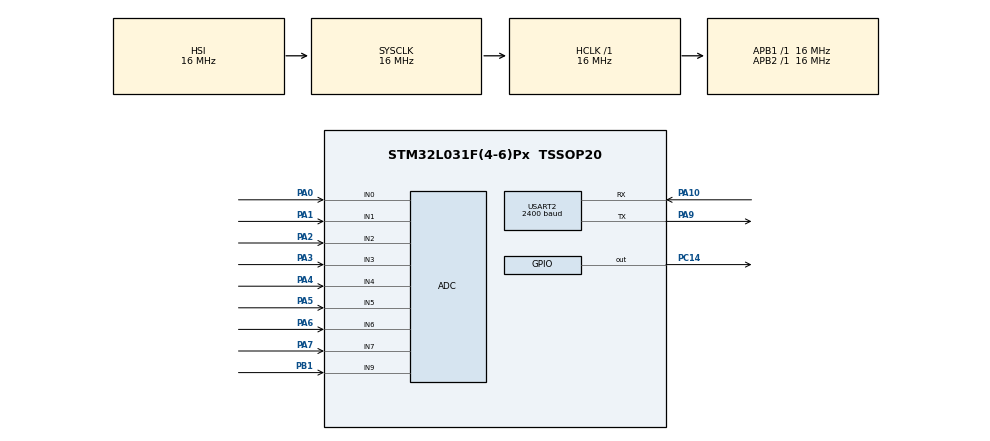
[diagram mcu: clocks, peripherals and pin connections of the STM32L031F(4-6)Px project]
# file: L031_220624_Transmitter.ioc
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Mcu.Family=STM32L0
RCC.MSI_VALUE=2097000
PA6.Mode=IN6
PA7.Mode=IN7
USART2.DMADisableonRxErrorParam=ADVFEATURE_DMA_DISABLEONRXERROR
PA10.Mode=Asynchronous
Dma.ADC.0.Mode=DMA_CIRCULAR
PA0-CK_IN.Mode=IN0
USART2.Parity=PARITY_EVEN
Dma.ADC.0.Priority=DMA_PRIORITY_VERY_HIGH
PC14-OSC32_IN.Signal=GPIO_Output
ADC.ClockPrescaler=ADC_CLOCK_ASYNC_DIV16
USART2.BaudRate=2400
RCC.SYSCLKSource=RCC_SYSCLKSOURCE_HSI
ProjectManager.StackSize=0x400
Dma.ADC.0.PeriphDataAlignment=DMA_PDATAALIGN_HALFWORD
PA3.Mode=IN3
PA13.Signal=SYS_SWDIO
ADC.DiscontinuousConvMode=DISABLE
RCC.HSI16_VALUE=16000000
PA9.Mode=Asynchronous
RCC.PLLDIV=RCC_PLLDIV_4
PA4.Mode=IN4
ProjectManager.TargetToolchain=STM32CubeIDE
Dma.ADC.0.PeriphInc=DMA_PINC_DISABLE
RCC.HCLKFreq_Value=16000000
RCC.APB2TimFreq_Value=16000000
PA9.Signal=USART2_TX
RCC.LSE_VALUE=32768
PA1.Signal=ADC_IN1
RCC.AHBFreq_Value=16000000
Dma.ADC.0.Direction=DMA_PERIPH_TO_MEMORY
ADC.SamplingTime=ADC_SAMPLETIME_160CYCLES_5
PA5.Signal=ADC_IN5
RCC.HSE_VALUE=8000000
ADC.DMAContinuousRequests=ENABLE
board=custom
USART2.VirtualMode-Asynchronous=VM_ASYNC
RCC.VCOOutputFreq_Value=64000000
RCC.PLLMUL=RCC_PLLMUL_4
PA0-CK_IN.Signal=ADC_IN0
RCC.APB2Freq_Value=16000000
PA1.Mode=IN1
ADC.ExternalTrigConvEdge=ADC_EXTERNALTRIGCONVEDGE_NONE
PA14.Mode=Serial_Wire
RCC.ADCFreq_Value=16000000
ADC.EOCSelection=ADC_EOC_SEQ_CONV
PA13.Mode=Serial_Wire
Mcu.Name=STM32L031F(4-6)Px
PA2.Signal=ADC_IN2
ADC.Overrun=ADC_OVR_DATA_OVERWRITTEN
Dma.ADC.0.MemInc=DMA_MINC_ENABLE
PA4.Signal=ADC_IN4
RCC.SYSCLKFreq_VALUE=16000000
Mcu.Package=TSSOP20
PA6.Signal=ADC_IN6
PB1.Signal=ADC_IN9
Dma.ADC.0.Instance=DMA1_Channel1
PA10.Signal=USART2_RX
PA14.Signal=SYS_SWCLK
ProjectManager.HeapSize=0x200
PB1.Mode=IN9
RCC.HSI_VALUE=16000000
Dma.ADC.0.MemDataAlignment=DMA_MDATAALIGN_HALFWORD
RCC.APB1TimFreq_Value=16000000
PA2.Mode=IN2
PC14-OSC32_IN.GPIO_PuPd=GPIO_PULLDOWN
NVIC.DMA1_Channel1_IRQn=true\:0\:0\:false\:false\:true\:false\:true
Dma.Request0=ADC
RCC.APB1Freq_Value=16000000
USART2.Mode=MODE_TX_RX
ADC.ContinuousConvMode=ENABLE
ADC.ExternalTrigConv=ADC_SOFTWARE_START
PA3.Signal=ADC_IN3
PA7.Signal=ADC_IN7
PA5.Mode=IN5
USART2.OverrunDisableParam=ADVFEATURE_OVERRUN_DISABLE

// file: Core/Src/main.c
/* USER CODE BEGIN Header */
/**
  ******************************************************************************
  * @file           : main.c
  * @brief          : Main program body
  ******************************************************************************
  * @attention
  *
  * <h2><center>&copy; Copyright (c) 2022 STMicroelectronics.
  * All rights reserved.</center></h2>
  *
  * This software component is licensed by ST under BSD 3-Clause license,
  * the "License"; You may not use this file except in compliance with the
  * License. You may obtain a copy of the License at:
  *                        opensource.org/licenses/BSD-3-Clause
  *
  ******************************************************************************
  */
/* USER CODE END Header */
#include "main.h"

/* USER CODE BEGIN Includes */
#include "stdio.h"
#include "adc.h"
#include "processing.h"
#include "transmission.h"

/* USER CODE END Includes */

ADC_HandleTypeDef hadc;
DMA_HandleTypeDef hdma_adc;

UART_HandleTypeDef huart2;

void SystemClock_Config(void);
static void MX_GPIO_Init(void);
static void MX_DMA_Init(void);
static void MX_ADC_Init(void);
static void MX_USART2_UART_Init(void);

int main(void)
{

  /* MCU Configuration--------------------------------------------------------*/

  /* Reset of all peripherals, Initializes the Flash interface and the Systick. */
  HAL_Init();

  /* Configure the system clock */
  SystemClock_Config();

  /* Initialize all configured peripherals */
  MX_GPIO_Init();
  MX_DMA_Init();
  MX_ADC_Init();
  MX_USART2_UART_Init();
  /* USER CODE BEGIN 2 */
  HAL_ADC_Start_DMA(&hadc, (uint32_t *)adcBuffer, buffLength);

  /* USER CODE END 2 */

  /* Infinite loop */
  while (1)
  {

  }
}

void SystemClock_Config(void)
{
  RCC_OscInitTypeDef RCC_OscInitStruct = {0};
  RCC_ClkInitTypeDef RCC_ClkInitStruct = {0};
  RCC_PeriphCLKInitTypeDef PeriphClkInit = {0};

  /** Configure the main internal regulator output voltage
  */
  __HAL_PWR_VOLTAGESCALING_CONFIG(PWR_REGULATOR_VOLTAGE_SCALE1);
  /** Initializes the RCC Oscillators according to the specified parameters
  * in the RCC_OscInitTypeDef structure.
  */
  RCC_OscInitStruct.OscillatorType = RCC_OSCILLATORTYPE_HSI;
  RCC_OscInitStruct.HSIState = RCC_HSI_ON;
  RCC_OscInitStruct.HSICalibrationValue = RCC_HSICALIBRATION_DEFAULT;
  RCC_OscInitStruct.PLL.PLLState = RCC_PLL_NONE;
  if (HAL_RCC_OscConfig(&RCC_OscInitStruct) != HAL_OK)
  {
    Error_Handler();
  }
  /** Initializes the CPU, AHB and APB buses clocks
  */
  RCC_ClkInitStruct.ClockType = RCC_CLOCKTYPE_HCLK|RCC_CLOCKTYPE_SYSCLK
                              |RCC_CLOCKTYPE_PCLK1|RCC_CLOCKTYPE_PCLK2;
  RCC_ClkInitStruct.SYSCLKSource = RCC_SYSCLKSOURCE_HSI;
  RCC_ClkInitStruct.AHBCLKDivider = RCC_SYSCLK_DIV1;
  RCC_ClkInitStruct.APB1CLKDivider = RCC_HCLK_DIV1;
  RCC_ClkInitStruct.APB2CLKDivider = RCC_HCLK_DIV1;

  if (HAL_RCC_ClockConfig(&RCC_ClkInitStruct, FLASH_LATENCY_0) != HAL_OK)
  {
    Error_Handler();
  }
  PeriphClkInit.PeriphClockSelection = RCC_PERIPHCLK_USART2;
  PeriphClkInit.Usart2ClockSelection = RCC_USART2CLKSOURCE_PCLK1;
  if (HAL_RCCEx_PeriphCLKConfig(&PeriphClkInit) != HAL_OK)
  {
    Error_Handler();
  }
}

static void MX_ADC_Init(void)
{

  ADC_ChannelConfTypeDef sConfig = {0};

  /** Configure the global features of the ADC (Clock, Resolution, Data Alignment and number of conversion)
  */
  hadc.Instance = ADC1;
  hadc.Init.OversamplingMode = DISABLE;
  hadc.Init.ClockPrescaler = ADC_CLOCK_ASYNC_DIV16;
  hadc.Init.Resolution = ADC_RESOLUTION_12B;
  hadc.Init.SamplingTime = ADC_SAMPLETIME_160CYCLES_5;
  hadc.Init.ScanConvMode = ADC_SCAN_DIRECTION_FORWARD;
  hadc.Init.DataAlign = ADC_DATAALIGN_RIGHT;
  hadc.Init.ContinuousConvMode = ENABLE;
  hadc.Init.DiscontinuousConvMode = DISABLE;
  hadc.Init.ExternalTrigConvEdge = ADC_EXTERNALTRIGCONVEDGE_NONE;
  hadc.Init.ExternalTrigConv = ADC_SOFTWARE_START;
  hadc.Init.DMAContinuousRequests = ENABLE;
  hadc.Init.EOCSelection = ADC_EOC_SEQ_CONV;
  hadc.Init.Overrun = ADC_OVR_DATA_OVERWRITTEN;
  hadc.Init.LowPowerAutoWait = DISABLE;
  hadc.Init.LowPowerFrequencyMode = ENABLE;
  hadc.Init.LowPowerAutoPowerOff = DISABLE;
  if (HAL_ADC_Init(&hadc) != HAL_OK)
  {
    Error_Handler();
  }
  /** Configure for the selected ADC regular channel to be converted.
  */
  sConfig.Channel = ADC_CHANNEL_0;
  sConfig.Rank = ADC_RANK_CHANNEL_NUMBER;
  if (HAL_ADC_ConfigChannel(&hadc, &sConfig) != HAL_OK)
  {
    Error_Handler();
  }
  /** Configure for the selected ADC regular channel to be converted.
  */
  sConfig.Channel = ADC_CHANNEL_1;
  if (HAL_ADC_ConfigChannel(&hadc, &sConfig) != HAL_OK)
  {
    Error_Handler();
  }
  /** Configure for the selected ADC regular channel to be converted.
  */
  sConfig.Channel = ADC_CHANNEL_2;
  if (HAL_ADC_ConfigChannel(&hadc, &sConfig) != HAL_OK)
  {
    Error_Handler();
  }
  /** Configure for the selected ADC regular channel to be converted.
  */
  sConfig.Channel = ADC_CHANNEL_3;
  if (HAL_ADC_ConfigChannel(&hadc, &sConfig) != HAL_OK)
  {
    Error_Handler();
  }
  /** Configure for the selected ADC regular channel to be converted.
  */
  sConfig.Channel = ADC_CHANNEL_4;
  if (HAL_ADC_ConfigChannel(&hadc, &sConfig) != HAL_OK)
  {
    Error_Handler();
  }
  /** Configure for the selected ADC regular channel to be converted.
  */
  sConfig.Channel = ADC_CHANNEL_5;
  if (HAL_ADC_ConfigChannel(&hadc, &sConfig) != HAL_OK)
  {
    Error_Handler();
  }
  /** Configure for the selected ADC regular channel to be converted.
  */
  sConfig.Channel = ADC_CHANNEL_6;
  if (HAL_ADC_ConfigChannel(&hadc, &sConfig) != HAL_OK)
  {
    Error_Handler();
  }
  /** Configure for the selected ADC regular channel to be converted.
  */
  sConfig.Channel = ADC_CHANNEL_7;
  if (HAL_ADC_ConfigChannel(&hadc, &sConfig) != HAL_OK)
  {
    Error_Handler();
  }
  /** Configure for the selected ADC regular channel to be converted.
  */
  sConfig.Channel = ADC_CHANNEL_9;
  if (HAL_ADC_ConfigChannel(&hadc, &sConfig) != HAL_OK)
  {
    Error_Handler();
  }

}

static void MX_USART2_UART_Init(void)
{

  huart2.Instance = USART2;
  huart2.Init.BaudRate = 2400;
  huart2.Init.WordLength = UART_WORDLENGTH_8B;
  huart2.Init.StopBits = UART_STOPBITS_1;
  huart2.Init.Parity = UART_PARITY_EVEN;
  huart2.Init.Mode = UART_MODE_TX_RX;
  huart2.Init.HwFlowCtl = UART_HWCONTROL_NONE;
  huart2.Init.OverSampling = UART_OVERSAMPLING_16;
  huart2.Init.OneBitSampling = UART_ONE_BIT_SAMPLE_DISABLE;
  huart2.AdvancedInit.AdvFeatureInit = UART_ADVFEATURE_RXOVERRUNDISABLE_INIT|UART_ADVFEATURE_DMADISABLEONERROR_INIT;
  huart2.AdvancedInit.OverrunDisable = UART_ADVFEATURE_OVERRUN_DISABLE;
  huart2.AdvancedInit.DMADisableonRxError = UART_ADVFEATURE_DMA_DISABLEONRXERROR;
  if (HAL_UART_Init(&huart2) != HAL_OK)
  {
    Error_Handler();
  }

}

static void MX_DMA_Init(void)
{

  /* DMA controller clock enable */
  __HAL_RCC_DMA1_CLK_ENABLE();

  /* DMA interrupt init */
  /* DMA1_Channel1_IRQn interrupt configuration */
  HAL_NVIC_SetPriority(DMA1_Channel1_IRQn, 0, 0);
  HAL_NVIC_EnableIRQ(DMA1_Channel1_IRQn);

}

static void MX_GPIO_Init(void)
{
  GPIO_InitTypeDef GPIO_InitStruct = {0};

  /* GPIO Ports Clock Enable */
  __HAL_RCC_GPIOC_CLK_ENABLE();
  __HAL_RCC_GPIOA_CLK_ENABLE();
  __HAL_RCC_GPIOB_CLK_ENABLE();

  /*Configure GPIO pin Output Level */
  HAL_GPIO_WritePin(GPIOC, GPIO_PIN_14, GPIO_PIN_RESET);

  /*Configure GPIO pin : PC14 */
  GPIO_InitStruct.Pin = GPIO_PIN_14;
  GPIO_InitStruct.Mode = GPIO_MODE_OUTPUT_PP;
  GPIO_InitStruct.Pull = GPIO_PULLDOWN;
  GPIO_InitStruct.Speed = GPIO_SPEED_FREQ_LOW;
  HAL_GPIO_Init(GPIOC, &GPIO_InitStruct);

}

/* USER CODE BEGIN 4 */
// Called when buffer is completely filled
void HAL_ADC_ConvCpltCallback(ADC_HandleTypeDef *hadc)
{
	scheduler();
}

/* USER CODE END 4 */

void Error_Handler(void)
{
  __disable_irq();
  while (1)
  {
  }
}

/************************ (C) COPYRIGHT STMicroelectronics *****END OF FILE****/
